# ICSSM0_COMMON_0_PR1_PROT_SLV register map
Vendor: Texas Instruments
Peripheral module from a debugger description file (folder am62x).
Registers are 32-bit, read-write, reset 0x0 unless marked. A register's access mark holds for its fields unless they carry their own. Offsets are as the file gives them; lines under a group give offsets from that group; [hi:lo] are bit positions; {n}, {i} and the like mark numbered series; 'fields as' and 'values as' point back to an identical list; <NAME> marks a mode.

## ICSSM0_COMMON_0_PR1_PROT_SLV
0x00 PR1_PROTECT__SLV__REGS_unlock_key
  [31:0] UNLOCK_KEY — UnLock Key Pattern 0x83E7_0B13 to UnLock 0x0000_0000 to Lock Must unlock to update MMRs
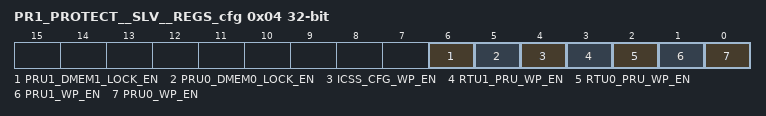
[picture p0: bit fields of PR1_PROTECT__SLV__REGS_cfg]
0x04 PR1_PROTECT__SLV__REGS_cfg
  [6] PRU1_DMEM1_LOCK_EN — Write Protect DMEM1 0: disable 1: enable When enabled only PRU1 can write to DMEM1
  [5] PRU0_DMEM0_LOCK_EN — Write Protect DMEM0 0: disable 1: enable When enabled only PRU0 can write to DMEM0
  [4] ICSS_CFG_WP_EN — Write Protect ICSS_CFG 0: disable 1: enable
  [3] RTU1_PRU_WP_EN — Write Protect RTU1_PRU access Debug IMEM 0: disable 1: enable
  [2] RTU0_PRU_WP_EN — Write Protect RTU0_PRU access Debug IMEM 0: disable 1: enable
  [1] PRU1_WP_EN — Write Protect PRU1 access Debug IMEM 0: disable 1: enable
  [0] PRU0_WP_EN — Write Protect PRU0 access Debug IMEM 0: disable 1: enable
